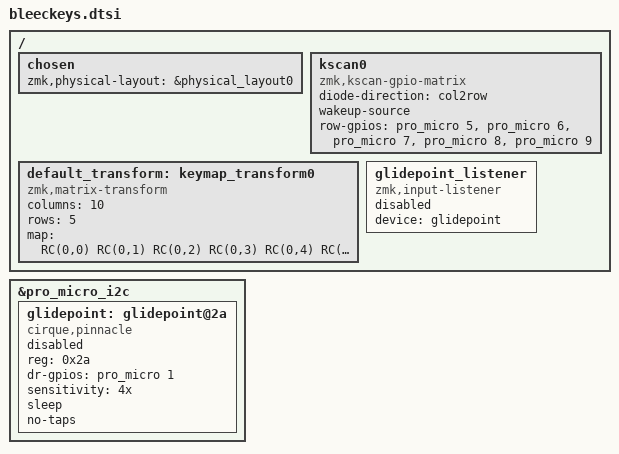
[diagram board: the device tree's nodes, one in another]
#include <dt-bindings/zmk/matrix_transform.h> // Put this with the other includes at the top of your dtsi
#include "bleeckeys-layouts.dtsi"


/ {
    chosen {
        //zephyr,display = &oled;
        zmk,physical-layout = &physical_layout0;
        //zmk,underglow = &led_strip;
        // Other chosen items
    };

    kscan0: kscan0 {
        compatible = "zmk,kscan-gpio-matrix";
        diode-direction = "col2row";
        wakeup-source;

        row-gpios
            = <&pro_micro 5 (GPIO_ACTIVE_HIGH | GPIO_PULL_DOWN)>
            , <&pro_micro 6 (GPIO_ACTIVE_HIGH | GPIO_PULL_DOWN)>
            , <&pro_micro 7 (GPIO_ACTIVE_HIGH | GPIO_PULL_DOWN)>
            , <&pro_micro 8 (GPIO_ACTIVE_HIGH | GPIO_PULL_DOWN)>
            , <&pro_micro 9 (GPIO_ACTIVE_HIGH | GPIO_PULL_DOWN)>
            ;

    };

    default_transform: keymap_transform0 {
        compatible = "zmk,matrix-transform";
        columns = <10>;
        rows = <5>;
        map = <
        //     /0       /1        /2        /3        /4           /5    
            RC(0,0)   RC(0,1)   RC(0,2)   RC(0,3)   RC(0,4)      RC(0,5) 
      >;
    };

    glidepoint_listener: glidepoint_listener {
        compatible = "zmk,input-listener";
        status = "disabled";
        device = <&glidepoint>;
    };
};

&pro_micro_i2c {
    status = "okay";

    glidepoint: glidepoint@2a {
        compatible = "cirque,pinnacle";
        reg = <0x2a>;
        status = "disabled";
        dr-gpios = <&pro_micro 1 (GPIO_ACTIVE_HIGH)>;

        sensitivity = "4x";
        sleep; 
        no-taps;
    };
};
